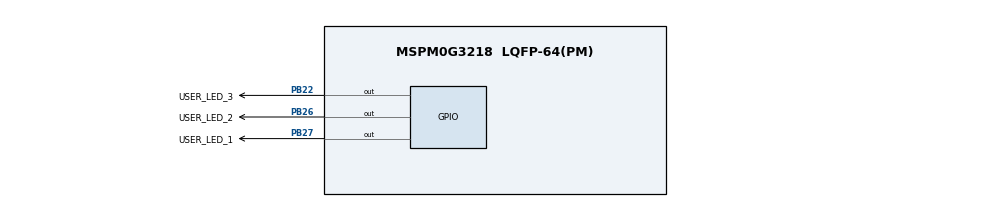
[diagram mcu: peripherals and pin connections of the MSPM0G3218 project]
//@cliArgs --device "MSPM0G321X" --package "LQFP-64(PM)" --part "Default"
//@v2CliArgs --device "MSPM0G3218" --package "LQFP-64(PM)"
// @cliArgs --board /ti/boards/LP_MSPM0G3218 --rtos nortos

/**
 * Import the modules used in this configuration.
 */
const ProjectConfig = scripting.addModule("/ti/project_config/ProjectConfig");
const Board         = scripting.addModule("/ti/driverlib/Board", {}, false);
const GPIO          = scripting.addModule("/ti/driverlib/GPIO", {}, false);
const GPIO1         = GPIO.addInstance();
const SYSCTL        = scripting.addModule("/ti/driverlib/SYSCTL", {}, false);

/**
 * Write custom configuration values to the imported modules.
 */
ProjectConfig.genDisable = true;

GPIO1.$name                         = "GPIO_LEDS";
GPIO1.associatedPins.create(3);
GPIO1.associatedPins[0].$name       = "USER_LED_1";
GPIO1.associatedPins[0].pin.$assign = "PB27";
GPIO1.associatedPins[1].$name       = "USER_LED_2";
GPIO1.associatedPins[1].pin.$assign = "PB26";
GPIO1.associatedPins[2].$name       = "USER_LED_3";
GPIO1.associatedPins[2].pin.$assign = "PB22";
